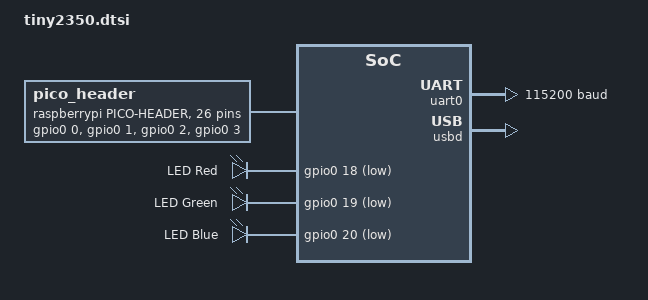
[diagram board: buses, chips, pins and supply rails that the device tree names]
/*
 * Copyright (c) 2024 Andrew Featherstone
 *
 * SPDX-License-Identifier: Apache-2.0
 */

#include <freq.h>

#include <zephyr/dt-bindings/pwm/pwm.h>

#include "tiny2350-pinctrl.dtsi"

/ {
	chosen {
		zephyr,sram = &sram0;
		zephyr,flash = &flash0;
		zephyr,flash-controller = &qmi;
		zephyr,console = &cdc_acm_uart0;
		zephyr,shell-uart = &cdc_acm_uart0;
	};

	pico_header: connector {
		compatible = "raspberrypi,pico-header";
		#gpio-cells = <2>;
		gpio-map-mask = <0xffffffff 0xffffffc0>;
		gpio-map-pass-thru = <0 0x3f>;
		gpio-map = <0 0 &gpio0 0 0>,	/* GP0 */
			   <1 0 &gpio0 1 0>,	/* GP1 */
			   <2 0 &gpio0 2 0>,	/* GP2 */
			   <3 0 &gpio0 3 0>,	/* GP3 */
			   <4 0 &gpio0 4 0>,	/* GP4 */
			   <5 0 &gpio0 5 0>,	/* GP5 */
			   <6 0 &gpio0 6 0>,	/* GP6 */
			   <7 0 &gpio0 7 0>,	/* GP7 */
			   <8 0 &gpio0 8 0>,	/* GP8 */
			   <9 0 &gpio0 9 0>,	/* GP9 */
			   <10 0 &gpio0 10 0>,	/* GP10 */
			   <11 0 &gpio0 11 0>,	/* GP11 */
			   <12 0 &gpio0 12 0>,	/* GP12 */
			   <13 0 &gpio0 13 0>,	/* GP13 */
			   <14 0 &gpio0 14 0>,	/* GP14 */
			   <15 0 &gpio0 15 0>,	/* GP15 */
			   <16 0 &gpio0 16 0>,	/* GP16 */
			   <17 0 &gpio0 17 0>,	/* GP17 */
			   <18 0 &gpio0 18 0>,	/* GP18 */
			   <19 0 &gpio0 19 0>,	/* GP19 */
			   <20 0 &gpio0 20 0>,	/* GP20 */
			   <21 0 &gpio0 21 0>,	/* GP21 */
			   <22 0 &gpio0 22 0>,	/* GP22 */
			   <26 0 &gpio0 26 0>,	/* GP26 */
			   <27 0 &gpio0 27 0>,	/* GP27 */
			   <28 0 &gpio0 28 0>;	/* GP28 */
	};

	leds {
		compatible = "gpio-leds";

		ledr: led_r {
			gpios = <&gpio0 18 GPIO_ACTIVE_LOW>;
			label = "LED Red";
		};

		ledg: led_g {
			gpios = <&gpio0 19 GPIO_ACTIVE_LOW>;
			label = "LED Green";
		};

		ledb: led_b {
			gpios = <&gpio0 20 GPIO_ACTIVE_LOW>;
			label = "LED Blue";
		};
	};
};

&flash0 {
	reg = <0x10000000 DT_SIZE_M(4)>;
};

&uart0 {
	current-speed = <115200>;
	status = "okay";
	pinctrl-0 = <&uart0_default>;
	pinctrl-names = "default";
};

gpio0_lo: &gpio0 {
	status = "okay";
};

&pwm {
	pinctrl-0 = <&pwm_ch4b_default>;
	pinctrl-names = "default";
	divider-int-0 = <255>;
};

zephyr_udc0: &usbd {
	status = "okay";

	cdc_acm_uart0: cdc_acm_uart0 {
		compatible = "zephyr,cdc-acm-uart";
	};
};

pico_serial: &uart0 {};

pico_serial0: &uart0 {};

/ {
	aliases {
		ledr = &ledr;
		ledg = &ledg;
		ledb = &ledb;
	};
};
